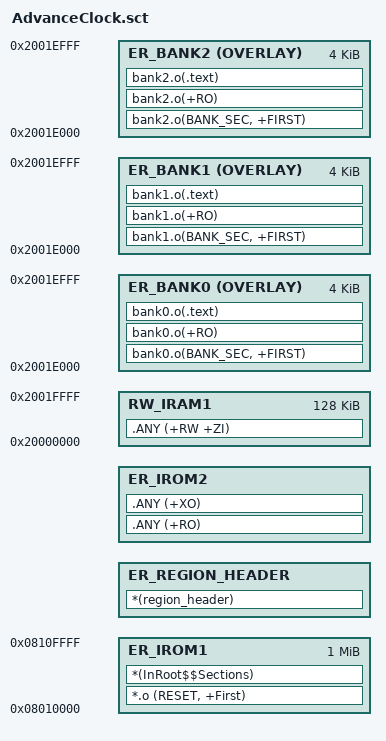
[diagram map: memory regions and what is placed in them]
; *************************************************************
; *** Scatter-Loading Description File generated by uVision ***
; *************************************************************

LR_IROM1 0x08010000 0x00100000  ; load region size_region
{    
  ER_IROM1 0x08010000 0x00100000   ; load address = execution address
  { 
   *.o (RESET, +First)
   *(InRoot$$Sections)
  }
  ER_REGION_HEADER +0
  {
    *(region_header)
  }
  ER_IROM2 +0
  {
    .ANY (+RO)
    .ANY (+XO)
  }
  RW_IRAM1 0x20000000 0x00020000  ; RW data
  {  
   .ANY (+RW +ZI)
  }
}

LR_BANK0 0x30000000  0x1000
{
  ER_BANK0 0x2001E000  OVERLAY  0x1000 
  {
    bank0.o(BANK_SEC, +FIRST)
    bank0.o(+RO)
    bank0.o(.text)
  }
}

LR_BANK1 0x30001000  0x1000
{
  ER_BANK1 0x2001E000  OVERLAY 0x1000 
  {
    bank1.o(BANK_SEC, +FIRST)
    bank1.o(+RO)
    bank1.o(.text)
  }
}

LR_BANK2 0x30002000  0x1000
{
  ER_BANK2 0x2001E000  OVERLAY 0x1000 
  {
    bank2.o(BANK_SEC, +FIRST)
    bank2.o(+RO)
    bank2.o(.text)
  }
}

